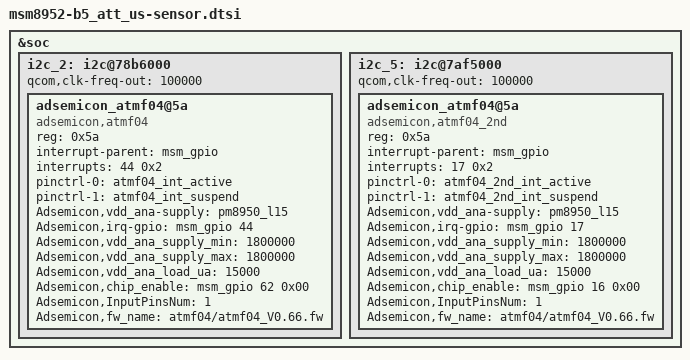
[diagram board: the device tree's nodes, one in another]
/*
 * Copyright (c) 2015, The Linux Foundation. All rights reserved.
 *
 * This program is free software; you can redistribute it and/or modify
 * it under the terms of the GNU General Public License version 2 and
 * only version 2 as published by the Free Software Foundation.
 *
 * This program is distributed in the hope that it will be useful,
 * but WITHOUT ANY WARRANTY; without even the implied warranty of
 * MERCHANTABILITY or FITNESS FOR A PARTICULAR PURPOSE.  See the
 * GNU General Public License for more details.
 */

// Cap sensor for LTE
&soc {
	i2c_2: i2c@78b6000 { /* BLSP1 QUP2 */
		qcom,clk-freq-out = <100000>; // I2C writing issue for cap sensor
	};

	i2c@78b6000 {
		adsemicon_atmf04@5a {
			compatible = "adsemicon,atmf04";
			status = "ok";
			reg = <0x5a>;
			interrupt-parent = <&msm_gpio>;
			interrupts = <44 0x2>;
			pinctrl-names = "default", "sleep";
			pinctrl-0 = <&atmf04_int_active>;
			pinctrl-1 = <&atmf04_int_suspend>;
			Adsemicon,vdd_ana-supply = <&pm8950_l15>;
			Adsemicon,irq-gpio = <&msm_gpio 44 0x00>;	/* Interrupt Pin */
			Adsemicon,vdd_ana_supply_min = <1800000>;
			Adsemicon,vdd_ana_supply_max = <1800000>;
			Adsemicon,vdd_ana_load_ua = <15000>;
			Adsemicon,chip_enable = <&msm_gpio 62 0x00>;  /* enable pin */
			Adsemicon,InputPinsNum = <1>;
			Adsemicon,fw_name = "atmf04/atmf04_V0.66.fw";
		};
	};

// Secondary Cap sensor for LTE DUAL
	i2c_5: i2c@7af5000 { /* BLSP2 QUP1 */
		qcom,clk-freq-out = <100000>; // I2C writing issue for cap sensor
	};

	i2c@7af5000 {
		adsemicon_atmf04@5a {
			//revision = "rev_b...";
			compatible = "adsemicon,atmf04_2nd";
			status = "ok";
			reg = <0x5a>;
			interrupt-parent = <&msm_gpio>;
			interrupts = <17 0x2>;
			pinctrl-names = "default", "sleep";
			pinctrl-0 = <&atmf04_2nd_int_active>;
			pinctrl-1 = <&atmf04_2nd_int_suspend>;
			Adsemicon,vdd_ana-supply = <&pm8950_l15>;
			Adsemicon,irq-gpio = <&msm_gpio 17 0x00>;	/* Interrupt Pin */
			Adsemicon,vdd_ana_supply_min = <1800000>;
			Adsemicon,vdd_ana_supply_max = <1800000>;
			Adsemicon,vdd_ana_load_ua = <15000>;
			Adsemicon,chip_enable = <&msm_gpio 16 0x00>;  /* enable pin */
			Adsemicon,InputPinsNum = <1>;
			Adsemicon,fw_name = "atmf04/atmf04_V0.66.fw";
		};
	};
};
